# PIC18F46Q24 register map
Vendor: Microchip
Registers are 8-bit, read-write, reset 0x0 unless marked. A register's access mark holds for its fields unless they carry their own. Addresses are absolute, and some are shared; only a register's first bit layout is shown; [hi:lo] are bit positions; {n}, {i} and the like mark numbered series.

## CONFIG — Configuration words, addresses in ProgramSpace
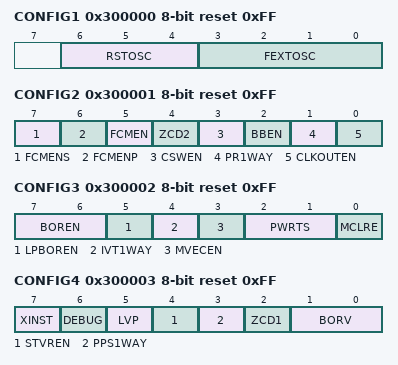
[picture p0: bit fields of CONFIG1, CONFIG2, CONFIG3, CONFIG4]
0x300000 CONFIG1 reset 0xFF — Configuration Byte 1
  [6:4] RSTOSC — Reset Oscillator Selection
    0=HFINTOSC_64MHZ (HFINTOSC with HFFRQ = 64 MHz and CDIV = 1:1); 2=EXTOSC_4PLL (EXTOSC with 4x PLL, with EXTOSC operating per FEXTOSC bits); 4=SOSC (Secondary Oscillator); 5=LFINTOSC (Low-Frequency Oscillator); 6=HFINTOSC_1MHZ (HFINTOSC with HFFRQ = 4 MHz and CDIV = 4:1); 7=EXTOSC (EXTOSC operating per FEXTOSC bits (device manufacturing default))
  [3:0] FEXTOSC — External Oscillator Selection
    0=LP (LP (crystal oscillator) optimized for 32.768 kHz); 2=HS_8MHZ (HS (crystal oscillator) up to 8 MHz); 3=HS_16MHZ (HS (crystal oscillator) up to 16 MHz); 4=HS_24MHZ (HS (crystal oscillator) up to 24 MHz); 5=HS_32MHZ (HS (crystal oscillator) up to 32 MHz); 6=OFF (Oscillator not enabled.); 13=ECL (EC (external clock) below 500 kHz); 14=ECM (EC (external clock) for 500 kHz to 8 MHz); 15=ECH (EC (external clock) above 8 MHz); 1=XT (XT (crystal oscillator) above 500 kHz, below 4 MHz)
0x300001 CONFIG2 reset 0xFF — Configuration byte 2
  [7] FCMENS — Fail-Safe Clock Monitor - Secondary XTAL Enable bit
    0=OFF (Fail-Safe Clock Monitor Disabled); 1=ON (Fail-Safe Clock Monitor enabled; timer will flag FSCMP bit and OSFIF interrupt on SOSC failure.)
  [6] FCMENP — Fail-Safe Clock Monitor - Primary XTAL Enable bit
    0=OFF (Fail-Safe Clock Monitor Disabled); 1=ON (Fail-Safe Clock Monitor enabled; timer will flag FSCMP bit and OSFIF interrupt on EXTOSC failure.)
  [5] FCMEN — Fail-Safe Clock Monitor Enable bit
    0=OFF (Fail-Safe Clock Monitor disabled); 1=ON (Fail-Safe Clock Monitor enabled)
  [4] ZCD2 — ZCD2 Disable bit
    1=OFF (ZCD2 module is disabled. ZCD2 can be enabled by setting the ZCDSEN bit of ZCDCON); 0=ON (ZCD2 module is always enabled; ZCDMD and ZCDSEN bits are ignored)
  [3] CSWEN — Clock Switch Enable bit
    0=OFF (The NOSC and NDIV bits cannot be changed by user software); 1=ON (Writing to NOSC and NDIV is allowed)
  [2] BBEN — Boot Block enable bit
    1=OFF (Boot block disabled); 0=ON (Boot block enabled)
  [1] PR1WAY — PRLOCKED One-Way Set Enable bit
    1=ON (PRLOCKED bit can be cleared and set only once); 0=OFF (PRLOCKED bit can be set and cleared repeatedly)
  [0] CLKOUTEN — Clock out Enable bit
    1=OFF (CLKOUT function is disabled); 0=ON (CLKOUT function is enabled)
0x300002 CONFIG3 reset 0xFF — Configuration byte 3
  [7:6] BOREN — Brown-out Reset Enable bits
    3=ON (Brown-out Reset enabled , SBOREN bit is ignored); 2=NOSLEEP (Brown-out Reset enabled while running, disabled in Sleep; SBOREN is ignored); 1=SBOREN (Brown-out Reset enabled according to SBOREN); 0=OFF (Brown-out Reset disabled)
  [5] LPBOREN — Low Power BOR Enable bit
    1=OFF (Low-Power BOR disabled); 0=ON (Low-Power BOR enabled)
  [4] IVT1WAY — IVTLOCK bit One-way set enable bit
    1=ON (IVTLOCKED bit can be cleared and set only once); 0=OFF (IVTLOCKED bit can be cleared and set repeatedly)
  [3] MVECEN — Multi-vector enable bit
    1=ON (Multi-vector enabled, Vector table used for interrupts); 0=OFF (Interrupt contoller does not use vector table to prioritze interrupts)
  [2:1] PWRTS — Power-up timer selection bits
    3=PWRT_OFF (PWRT is disabled); 2=PWRT_64 (PWRT set at 64ms); 1=PWRT_16 (PWRT set at 16ms); 0=PWRT_1 (PWRT set at 1ms)
  [0] MCLRE — MCLR Enable bit
    1=EXTMCLR (If LVP = 0, MCLR pin is MCLR; If LVP = 1, RE3 pin function is MCLR); 0=INTMCLR (If LVP = 0, MCLR pin function is port defined function; If LVP =1, RE3 pin fuction is MCLR)
0x300003 CONFIG4 reset 0xFF — Configuration byte 4
  [7] XINST — Extended Instruction Set Enable bit
    1=OFF (Extended Instruction Set and Indexed Addressing Mode disabled); 0=ON (Extended Instruction Set and Indexed Addressing Mode enabled)
  [6] DEBUG — Background Debugger
    1=OFF (Background Debugger disabled); 0=ON (Background Debugger enabled)
  [5] LVP — Low Voltage Programming Enable bit
    1=ON (Low voltage programming enabled. MCLR/VPP pin function is MCLR. MCLRE configuration bit is ignored); 0=OFF (HV on MCLR/VPP must be used for programming)
  [4] STVREN — Stack Full/Underflow Reset Enable bit
    1=ON (Stack full/underflow will cause Reset); 0=OFF (Stack full/underflow will not cause Reset)
  [3] PPS1WAY — PPSLOCK bit One-Way Set Enable bit
    1=ON (PPSLOCKED bit can be cleared and set only once; PPS registers remain locked after one clear/set cycle); 0=OFF (PPSLOCKED bit can be set and cleared repeatedly (subject to the unlock sequence))
  [2] ZCD1 — ZCD1 Disable bit
    1=OFF (ZCD1 module is disabled. ZCD1 can be enabled by setting the ZCDSEN bit of ZCDCON); 0=ON (ZCD1 module is always enabled; ZCDMD and ZCDSEN bits are ignored)
  [1:0] BORV — Brown-out Reset Voltage Selection bits
    3=VBOR_1P9 (Brown-out Reset Voltage (VBOR) set to 1.9V); 2=VBOR_2P45 (Brown-out Reset Voltage (VBOR) set to 2.45V); 1=VBOR_2P7 (Brown-out Reset Voltage (VBOR) set to 2.7V); 0=VBOR_2P85 (Brown-out Reset Voltage (VBOR) set to 2.85V)
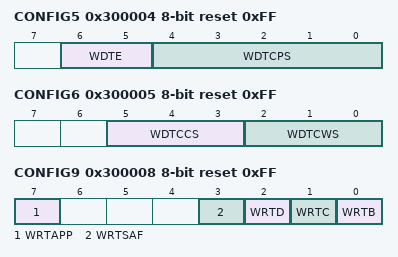
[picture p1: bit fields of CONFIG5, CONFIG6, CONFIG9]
0x300004 CONFIG5 reset 0xFF — Configuration byte 5
  [6:5] WDTE — WDT operating mode
    0=OFF (WDT Disabled; SEN is ignored); 1=SEN (WDT enabled/disabled by SEN bit); 2=NSLEEP (WDT enabled while sleep=0, suspended when sleep=1; SEN ignored); 3=ON (WDT enabled regardless of sleep; SEN is ignored)
  [4:0] WDTCPS — WDT Period selection bits
    0=Divider ratio 1:32; 1=Divider ratio 1:64; 2=Divider ratio 1:128; 3=Divider ratio 1:256; 4=Divider ratio 1:512; 5=Divider ratio 1:1024; 6=Divider ratio 1:2048; 7=Divider ratio 1:4096; 8=Divider ratio 1:8192; 9=Divider ratio 1:16384; 10=Divider ratio 1:32768; 11=Divider ratio 1:65536; 12=Divider ratio 1:131072; 13=Divider ratio 1:262144; 14=Divider ratio 1:524288; 15=Divider ratio 1:1048576; 16=Divider ratio 1:2097152; 17=Divider ratio 1:4194304; 18=Divider ratio 1:8388608; {v}=Divider ratio 1:32 (v=19..30); 31=Divider ratio 1:65536; software control of WDTPS
0x300005 CONFIG6 reset 0xFF — Configuration byte 6
  [5:3] WDTCCS — WDT input clock selector
    0=LFINTOSC (WDT reference clock is the 31.0 kHz LFINTOSC); 1=MFINTOSC (WDT reference clock is the 31.25 kHz MFINTOSC); 2=SOSC (WDT reference clock is SOSC); 7=SC (Software Control)
  [2:0] WDTCWS — WDT Window Select bits
    0=window delay = 87.5; no software control; keyed access required; 1=window delay = 75 percent of time; no software control; keyed access required; 2=window delay = 62.5 percent of time; no software control; keyed access required; 3=window delay = 50 percent of time; no software control; keyed access required; 4=window delay = 37.5 percent of time; no software control; keyed access required; 5=window delay = 25 percent of time; no software control; keyed access required; 6=window always open (100%); no software control; keyed access required; 7=window always open (100%); software control; keyed access not required
0x300006 CONFIG7 reset 0xFF — Configuration byte 7
  [7:0] BBSIZE — Boot Block Size Selection bits
    127=Boot Block size is 16384 words; 126=Boot Block size is 16256 words; 125=Boot Block size is 16128 words; 124=Boot Block size is 16000 words; 123=Boot Block size is 15872 words; 122=Boot Block size is 15744 words; 121=Boot Block size is 15616 words; 120=Boot Block size is 15488 words; 119=Boot Block size is 15360 words; 118=Boot Block size is 15232 words; 117=Boot Block size is 15104 words; 116=Boot Block size is 14976 words; 115=Boot Block size is 14848 words; 114=Boot Block size is 14720 words; 113=Boot Block size is 14592 words; 112=Boot Block size is 14464 words; 111=Boot Block size is 14336 words; 110=Boot Block size is 14208 words; 109=Boot Block size is 14080 words; 108=Boot Block size is 13952 words; 107=Boot Block size is 13824 words; 106=Boot Block size is 13696 words; 105=Boot Block size is 13568 words; 104=Boot Block size is 13440 words; 103=Boot Block size is 13312 words; 102=Boot Block size is 13184 words; 101=Boot Block size is 13056 words; 100=Boot Block size is 12928 words; 99=Boot Block size is 12800 words; 98=Boot Block size is 12672 words; 97=Boot Block size is 12544 words; 96=Boot Block size is 12416 words; 95=Boot Block size is 12288 words; 94=Boot Block size is 12160 words; 93=Boot Block size is 12032 words; 92=Boot Block size is 11904 words; 91=Boot Block size is 11776 words; 90=Boot Block size is 11648 words; 89=Boot Block size is 11520 words; 88=Boot Block size is 11392 words; 87=Boot Block size is 11264 words; 86=Boot Block size is 11136 words; 85=Boot Block size is 11008 words; 84=Boot Block size is 10880 words; 83=Boot Block size is 10752 words; 82=Boot Block size is 10624 words; 81=Boot Block size is 10496 words; 80=Boot Block size is 10368 words; 79=Boot Block size is 10240 words; 78=Boot Block size is 10112 words; 77=Boot Block size is 9984 words; 76=Boot Block size is 9856 words; 75=Boot Block size is 9728 words; 74=Boot Block size is 9600 words; 73=Boot Block size is 9472 words; 72=Boot Block size is 9344 words; 71=Boot Block size is 9216 words; 70=Boot Block size is 9088 words; 69=Boot Block size is 8960 words; 68=Boot Block size is 8832 words; 67=Boot Block size is 8704 words; 66=Boot Block size is 8576 words; 65=Boot Block size is 8448 words; 64=Boot Block size is 8320 words; 63=Boot Block size is 8192 words; 62=Boot Block size is 8064 words; 61=Boot Block size is 7936 words; 60=Boot Block size is 7808 words; 59=Boot Block size is 7680 words; 58=Boot Block size is 7552 words; 57=Boot Block size is 7424 words; 56=Boot Block size is 7296 words; 55=Boot Block size is 7168 words; 54=Boot Block size is 7040 words; 53=Boot Block size is 6912 words; 52=Boot Block size is 6784 words; 51=Boot Block size is 6656 words; 50=Boot Block size is 6528 words; 49=Boot Block size is 6400 words; 48=Boot Block size is 6272 words; 47=Boot Block size is 6144 words; 46=Boot Block size is 6016 words; 45=Boot Block size is 5888 words; 44=Boot Block size is 5760 words; 43=Boot Block size is 5632 words; 42=Boot Block size is 5504 words; 41=Boot Block size is 5376 words; 40=Boot Block size is 5248 words; 39=Boot Block size is 5120 words; 38=Boot Block size is 4992 words; 37=Boot Block size is 4864 words; 36=Boot Block size is 4736 words; 35=Boot Block size is 4608 words; 34=Boot Block size is 4480 words; 33=Boot Block size is 4352 words; 32=Boot Block size is 4224 words; 31=Boot Block size is 4096 words; 30=Boot Block size is 3968 words; 29=Boot Block size is 3840 words; 28=Boot Block size is 3712 words; 27=Boot Block size is 3584 words; 26=Boot Block size is 3456 words; 25=Boot Block size is 3328 words; 24=Boot Block size is 3200 words; 23=Boot Block size is 3072 words; 22=Boot Block size is 2944 words; 21=Boot Block size is 2816 words; 20=Boot Block size is 2688 words; 19=Boot Block size is 2560 words; 18=Boot Block size is 2432 words; 17=Boot Block size is 2304 words; 16=Boot Block size is 2176 words; 15=Boot Block size is 2048 words; 14=Boot Block size is 1920 words; 13=Boot Block size is 1792 words; 12=Boot Block size is 1664 words; 11=Boot Block size is 1536 words; 10=Boot Block size is 1408 words; 9=Boot Block size is 1280 words; 8=Boot Block size is 1152 words; 7=Boot Block size is 1024 words; 6=Boot Block size is 896 words; 5=Boot Block size is 768 words; 4=Boot Block size is 640 words; 3=Boot Block size is 512 words; 2=Boot Block size is 384 words; 1=Boot Block size is 256 words; 0=Boot Block size is 128 words
0x300008 CONFIG9 reset 0xFF — Configuration byte 9
  [7] WRTAPP — Application Block write protection bit
    1=OFF (Application Block not write protected); 0=ON (Application Block write protected)
  [3] WRTSAF — SAF Write protection bit
    1=OFF (SAF not Write Protected); 0=ON (SAF Write Protected)
  [2] WRTD — Data EEPROM Write Protection bit
    1=OFF (Data EEPROM not Write protected); 0=ON (Data EEPROM Write protected)
  [1] WRTC — Configuration Register Write Protection bit
    1=OFF (Configuration registers not Write protected); 0=ON (Configuration registers Write protected)
  [0] WRTB — Boot Block Write Protection bit
    1=OFF (Boot Block not Write protected); 0=ON (Boot Block Write protected)
0x300009 CONFIG10 reset 0xFF — Configuration byte 11
  [0] CP — PFM Code Protection bit
    1=OFF (PFM code protection disabled); 0=ON (PFM code protection enabled)
0x30000A CONFIG11 reset 0xFF — Configuration byte 10
  [0] CPD — Data EEPROM Code Protection bit
    1=OFF (Data EEPROM code protection disabled); 0=ON (Data EEPROM code protection enabled)
0x300018 CONFIG13 reset 0xFF
  [0] SAFLOCK — SAF Lock Enable bit
    1=OFF (SAF Lock disabled); 0=ON (SAF Lock enabled, SAF areas are locked and SAFSZ bits cannot be erased)
0x300019 CONFIG8 reset 0xFF — Configuration byte 8
  [7:0] SAFSZ — SAF Block Size Selection bits
    255=SAFSZ_DIS (Disabled); 254=Last 128 words of PFM; self write operation depends on WRTSAF bit in CONFIG9; 252=Last 256 words of PFM; self write operation depends on WRTSAF bit in CONFIG9; 248=Last 384 words of PFM; self write operation depends on WRTSAF bit in CONFIG9; 240=Last 512 words of PFM; self write operation depends on WRTSAF bit in CONFIG9; 224=Last 640 words of PFM; self write operation depends on WRTSAF bit in CONFIG9; 192=Last 768 words of PFM; self write operation depends on WRTSAF bit in CONFIG9; 128=Last 896 words of PFM; self write operation depends on WRTSAF bit in CONFIG9; 0=Last 1024 words of PFM; self write operation depends on WRTSAF bit in CONFIG9
0x30001C CONFIG12 reset 0xFF
  [0] ICSPDIS — ICD / ICSP Disable bit
    1=OFF (ICSP and ICD interface fully enabled); 0=ON (ICSP and ICD interface fully disabled)
